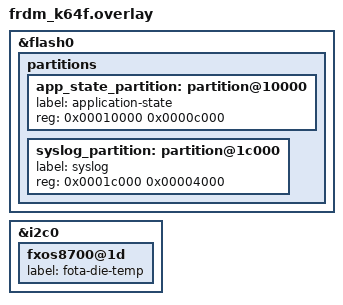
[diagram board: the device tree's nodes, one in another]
&flash0 {
	partitions {
		app_state_partition: partition@10000 {
			label = "application-state";
			reg = <0x00010000 0x0000c000>;
		};

		syslog_partition: partition@1c000 {
			label = "syslog";
			reg = <0x0001c000 0x00004000>;
		};
	};
};

&i2c0 {
	fxos8700@1d {
		label = "fota-die-temp";
	};
};
